# DDR16SS_DDR16SS_CTLPHY_WRAP_CTL_CFG_CTLCFG_0F308000h register map
Vendor: Texas Instruments
Registers are 32-bit, read-write, reset 0x0 unless marked. A register's access mark holds for its fields unless they carry their own. Offsets are as the file gives them; [hi:lo] are bit positions; lines under a group give offsets from that group; {n}, {i} and the like mark numbered series.

## DDR16SS_CTLPHY_WRAP_CTL_CFG_CTLCFG (part 4 of 11)
{0x0+4i} DDR16SS_CTLPHY_WRAP_CTL_CFG_CTLCFG_DENALI_CTL_{i} (i=239..241)
  [16:0] MR5_DATA_F{i-239}_1 — Data to program into memory mode register 5. FC={i-239} Reset Source: ctl_amod_g_rst_n
{0x0+4i} DDR16SS_CTLPHY_WRAP_CTL_CFG_CTLCFG_DENALI_CTL_{i} (i=242..244)
  [16:0] MR6_DATA_F{i-242}_0 — Data to program into memory mode register 6. FC={i-242} Reset Source: ctl_amod_g_rst_n
0x3D4 DDR16SS_CTLPHY_WRAP_CTL_CFG_CTLCFG_DENALI_CTL_245
  [16:0] MR6_DATA_F0_1 — Data to program into memory mode register 6. FC=0 Reset Source: ctl_amod_g_rst_n
0x3D8 DDR16SS_CTLPHY_WRAP_CTL_CFG_CTLCFG_DENALI_CTL_246
  [16:0] MR6_DATA_F1_1 — Data to program into memory mode register 6. FC=1 Reset Source: ctl_amod_g_rst_n
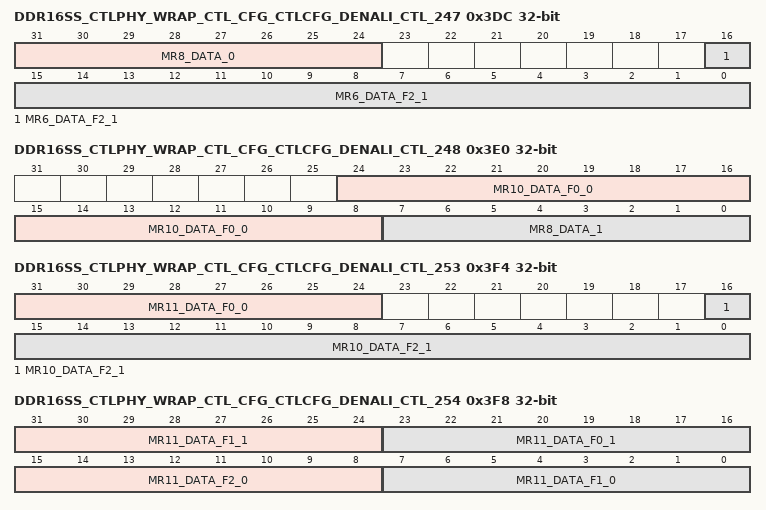
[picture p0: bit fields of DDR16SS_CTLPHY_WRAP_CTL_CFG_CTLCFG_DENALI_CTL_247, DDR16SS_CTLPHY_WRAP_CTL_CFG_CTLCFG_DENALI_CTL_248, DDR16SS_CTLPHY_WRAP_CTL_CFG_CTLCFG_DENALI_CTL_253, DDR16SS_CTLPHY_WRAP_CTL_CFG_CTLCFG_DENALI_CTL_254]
0x3DC DDR16SS_CTLPHY_WRAP_CTL_CFG_CTLCFG_DENALI_CTL_247 access per field
  [31:24] MR8_DATA_0 ro — Data to program into memory mode register 8 for each chip select. READ-ONLY. Reset Source: ctl_amod_g_rst_n
  [16:0] MR6_DATA_F2_1 rw — Data to program into memory mode register 6. FC=2 Reset Source: ctl_amod_g_rst_n
0x3E0 DDR16SS_CTLPHY_WRAP_CTL_CFG_CTLCFG_DENALI_CTL_248 access per field
  [24:8] MR10_DATA_F0_0 rw — Data to program into memory mode register 10. FC=0 Reset Source: ctl_amod_g_rst_n
  [7:0] MR8_DATA_1 ro — Data to program into memory mode register 8 for each chip select. READ-ONLY. Reset Source: ctl_amod_g_rst_n
0x3E4 DDR16SS_CTLPHY_WRAP_CTL_CFG_CTLCFG_DENALI_CTL_249
  [16:0] MR10_DATA_F1_0 — Data to program into memory mode register 10. FC=1 Reset Source: ctl_amod_g_rst_n
0x3E8 DDR16SS_CTLPHY_WRAP_CTL_CFG_CTLCFG_DENALI_CTL_250
  [16:0] MR10_DATA_F2_0 — Data to program into memory mode register 10. FC=2 Reset Source: ctl_amod_g_rst_n
0x3EC DDR16SS_CTLPHY_WRAP_CTL_CFG_CTLCFG_DENALI_CTL_251
  [16:0] MR10_DATA_F0_1 — Data to program into memory mode register 10. FC=0 Reset Source: ctl_amod_g_rst_n
0x3F0 DDR16SS_CTLPHY_WRAP_CTL_CFG_CTLCFG_DENALI_CTL_252
  [16:0] MR10_DATA_F1_1 — Data to program into memory mode register 10. FC=1 Reset Source: ctl_amod_g_rst_n
0x3F4 DDR16SS_CTLPHY_WRAP_CTL_CFG_CTLCFG_DENALI_CTL_253
  [31:24] MR11_DATA_F0_0 — Data to program into memory mode register 11. FC=0 Reset Source: ctl_amod_g_rst_n
  [16:0] MR10_DATA_F2_1 — Data to program into memory mode register 10. FC=2 Reset Source: ctl_amod_g_rst_n
0x3F8 DDR16SS_CTLPHY_WRAP_CTL_CFG_CTLCFG_DENALI_CTL_254
  [31:24] MR11_DATA_F1_1 — Data to program into memory mode register 11. FC=1 Reset Source: ctl_amod_g_rst_n
  [23:16] MR11_DATA_F0_1 — Data to program into memory mode register 11. FC=0 Reset Source: ctl_amod_g_rst_n
  [15:8] MR11_DATA_F2_0 — Data to program into memory mode register 11. FC=2 Reset Source: ctl_amod_g_rst_n
  [7:0] MR11_DATA_F1_0 — Data to program into memory mode register 11. FC=1 Reset Source: ctl_amod_g_rst_n
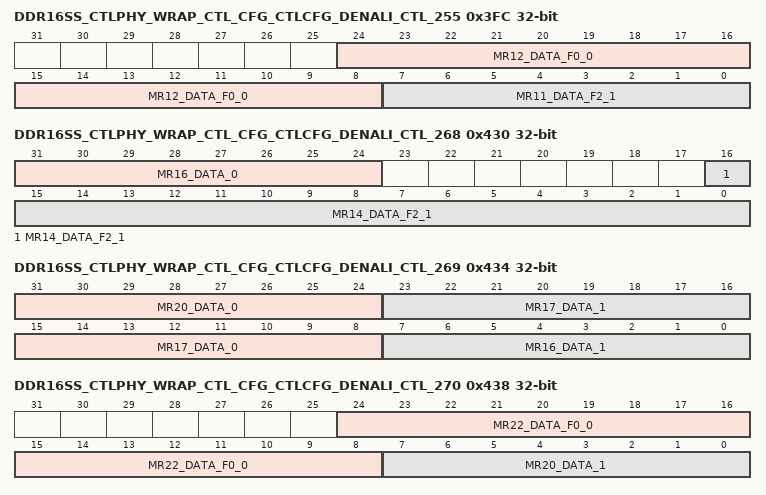
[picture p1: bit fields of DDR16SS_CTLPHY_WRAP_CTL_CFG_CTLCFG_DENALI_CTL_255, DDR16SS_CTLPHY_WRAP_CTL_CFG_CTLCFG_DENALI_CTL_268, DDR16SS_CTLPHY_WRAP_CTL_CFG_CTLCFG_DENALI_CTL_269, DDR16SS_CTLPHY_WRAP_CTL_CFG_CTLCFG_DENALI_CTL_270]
0x3FC DDR16SS_CTLPHY_WRAP_CTL_CFG_CTLCFG_DENALI_CTL_255
  [24:8] MR12_DATA_F0_0 — Data to program into memory mode register 12. FC=0 Reset Source: ctl_amod_g_rst_n
  [7:0] MR11_DATA_F2_1 — Data to program into memory mode register 11. FC=2 Reset Source: ctl_amod_g_rst_n
0x400 DDR16SS_CTLPHY_WRAP_CTL_CFG_CTLCFG_DENALI_CTL_256
  [16:0] MR12_DATA_F1_0 — Data to program into memory mode register 12. FC=1 Reset Source: ctl_amod_g_rst_n
0x404 DDR16SS_CTLPHY_WRAP_CTL_CFG_CTLCFG_DENALI_CTL_257
  [16:0] MR12_DATA_F2_0 — Data to program into memory mode register 12. FC=2 Reset Source: ctl_amod_g_rst_n
{0x0+4i} DDR16SS_CTLPHY_WRAP_CTL_CFG_CTLCFG_DENALI_CTL_{i} (i=258..260)
  [16:0] MR12_DATA_F{i-258}_1 — Data to program into memory mode register 12. FC={i-258} Reset Source: ctl_amod_g_rst_n
0x414 DDR16SS_CTLPHY_WRAP_CTL_CFG_CTLCFG_DENALI_CTL_261
  [16:0] MR13_DATA_0 — Data to program into memory mode register 13. Reset Source: ctl_amod_g_rst_n
0x418 DDR16SS_CTLPHY_WRAP_CTL_CFG_CTLCFG_DENALI_CTL_262
  [16:0] MR13_DATA_1 — Data to program into memory mode register 13. Reset Source: ctl_amod_g_rst_n
{0x0+4i} DDR16SS_CTLPHY_WRAP_CTL_CFG_CTLCFG_DENALI_CTL_{i} (i=263..265)
  [16:0] MR14_DATA_F{i-263}_0 — Data to program into memory mode register 14. FC={i-263} Reset Source: ctl_amod_g_rst_n
0x428 DDR16SS_CTLPHY_WRAP_CTL_CFG_CTLCFG_DENALI_CTL_266
  [16:0] MR14_DATA_F0_1 — Data to program into memory mode register 14. FC=0 Reset Source: ctl_amod_g_rst_n
0x42C DDR16SS_CTLPHY_WRAP_CTL_CFG_CTLCFG_DENALI_CTL_267
  [16:0] MR14_DATA_F1_1 — Data to program into memory mode register 14. FC=1 Reset Source: ctl_amod_g_rst_n
0x430 DDR16SS_CTLPHY_WRAP_CTL_CFG_CTLCFG_DENALI_CTL_268
  [31:24] MR16_DATA_0 — Data to program into memory mode register 16. Reset Source: ctl_amod_g_rst_n
  [16:0] MR14_DATA_F2_1 — Data to program into memory mode register 14. FC=2 Reset Source: ctl_amod_g_rst_n
0x434 DDR16SS_CTLPHY_WRAP_CTL_CFG_CTLCFG_DENALI_CTL_269
  [31:24] MR20_DATA_0 — Data to program into memory mode register 20. Reset Source: ctl_amod_g_rst_n
  [23:16] MR17_DATA_1 — Data to program into memory mode register 17. Reset Source: ctl_amod_g_rst_n
  [15:8] MR17_DATA_0 — Data to program into memory mode register 17. Reset Source: ctl_amod_g_rst_n
  [7:0] MR16_DATA_1 — Data to program into memory mode register 16. Reset Source: ctl_amod_g_rst_n
0x438 DDR16SS_CTLPHY_WRAP_CTL_CFG_CTLCFG_DENALI_CTL_270
  [24:8] MR22_DATA_F0_0 — Data to program into memory mode register 22. FC=0 Reset Source: ctl_amod_g_rst_n
  [7:0] MR20_DATA_1 — Data to program into memory mode register 20. Reset Source: ctl_amod_g_rst_n
0x43C DDR16SS_CTLPHY_WRAP_CTL_CFG_CTLCFG_DENALI_CTL_271
  [16:0] MR22_DATA_F1_0 — Data to program into memory mode register 22. FC=1 Reset Source: ctl_amod_g_rst_n
0x440 DDR16SS_CTLPHY_WRAP_CTL_CFG_CTLCFG_DENALI_CTL_272
  [16:0] MR22_DATA_F2_0 — Data to program into memory mode register 22. FC=2 Reset Source: ctl_amod_g_rst_n
{0x0+4i} DDR16SS_CTLPHY_WRAP_CTL_CFG_CTLCFG_DENALI_CTL_{i} (i=273..275)
  [16:0] MR22_DATA_F{i-273}_1 — Data to program into memory mode register 22. FC={i-273} Reset Source: ctl_amod_g_rst_n
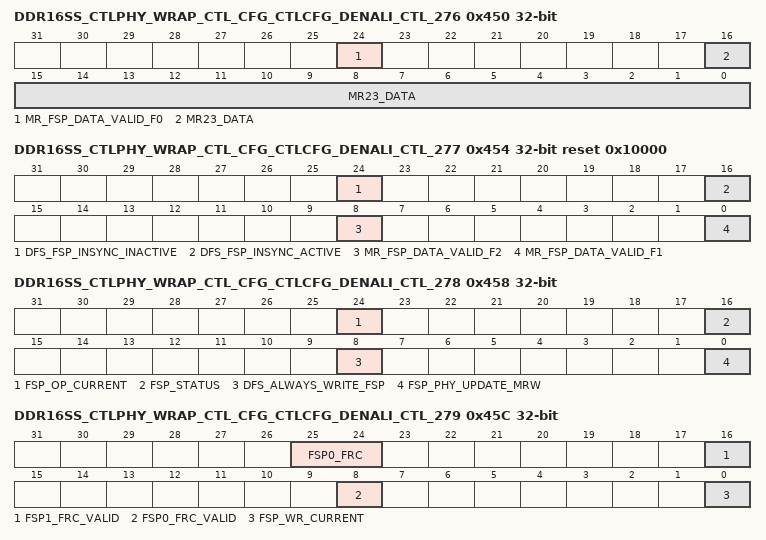
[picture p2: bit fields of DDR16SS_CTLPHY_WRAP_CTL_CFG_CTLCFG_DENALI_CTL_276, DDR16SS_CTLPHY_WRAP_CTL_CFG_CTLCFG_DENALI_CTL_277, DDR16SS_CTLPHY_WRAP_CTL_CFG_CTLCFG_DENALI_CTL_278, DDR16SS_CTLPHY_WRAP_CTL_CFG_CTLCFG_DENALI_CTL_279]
0x450 DDR16SS_CTLPHY_WRAP_CTL_CFG_CTLCFG_DENALI_CTL_276
  [24] MR_FSP_DATA_VALID_F0 — Indicates that, at this frequency, memory was trained and the associated data has been loaded into the MRx_DATA parameter[s]. Value of 1 means memory was trained. FC=0 Reset Source: ctl_amod_g_rst_n
  [16:0] MR23_DATA — Data to program into memory mode register 23. Reset Source: ctl_amod_g_rst_n
0x454 DDR16SS_CTLPHY_WRAP_CTL_CFG_CTLCFG_DENALI_CTL_277 access per field reset 0x10000
  [24] DFS_FSP_INSYNC_INACTIVE ro — When cleared, this indicates that the contents in memcd_param is new that the values in memory's MRx FSP reg and if a dfs occurs, they need to be updated. READ-ONLY Reset Source: ctl_amod_g_rst_n
  [16] DFS_FSP_INSYNC_ACTIVE ro — When cleared, this indicates that the contents in memcd_param is new that the values in memory's MRx FSP reg and if a dfs occurs, they need to be updated. READ-ONLY Reset Source: ctl_amod_g_rst_n
  [8] MR_FSP_DATA_VALID_F2 rw — Indicates that, at this frequency, memory was trained and the associated data has been loaded into the MRx_DATA parameter[s]. Value of 1 means memory was trained. FC=2 Reset Source: ctl_amod_g_rst_n
  [0] MR_FSP_DATA_VALID_F1 rw — Indicates that, at this frequency, memory was trained and the associated data has been loaded into the MRx_DATA parameter[s]. Value of 1 means memory was trained. FC=1 Reset Source: ctl_amod_g_rst_n
0x458 DDR16SS_CTLPHY_WRAP_CTL_CFG_CTLCFG_DENALI_CTL_278
  [24] FSP_OP_CURRENT — Reports which FSP set the memory is currently using. Reset Source: ctl_amod_g_rst_n
  [16] FSP_STATUS — Indicates that a DFS event caused the FSP mode registers to be updated. Value of 1 means that the FSP mode registers were changed. Reset Source: ctl_amod_g_rst_n
  [8] DFS_ALWAYS_WRITE_FSP — Forces all FSP mode registers to be written by the controller during a DFS event. Set to 1 to force the write. Reset Source: ctl_amod_g_rst_n
  [0] FSP_PHY_UPDATE_MRW — Identifies the logic responsible for updating MR12 and MR14 in memory. Clear to 0 for the controller, or set to 1 for the PHY or PI. Reset Source: ctl_amod_g_rst_n
0x45C DDR16SS_CTLPHY_WRAP_CTL_CFG_CTLCFG_DENALI_CTL_279
  [25:24] FSP0_FRC — Identifies which of the controller's frequency copy is associated with FSP0. Reset Source: ctl_amod_g_rst_n
  [16] FSP1_FRC_VALID — Specifies whether the FSP set defined in the FSP1_FRC parameter reflects the frequency used to program the FSP1 registers. Reset Source: ctl_amod_g_rst_n
  [8] FSP0_FRC_VALID — Specifies whether the FSP set defined in the FSP0_FRC parameter reflects the frequency used to program the FSP0 registers. Reset Source: ctl_amod_g_rst_n
  [0] FSP_WR_CURRENT — Reports which FSP set the memory will target with write commands. Reset Source: ctl_amod_g_rst_n
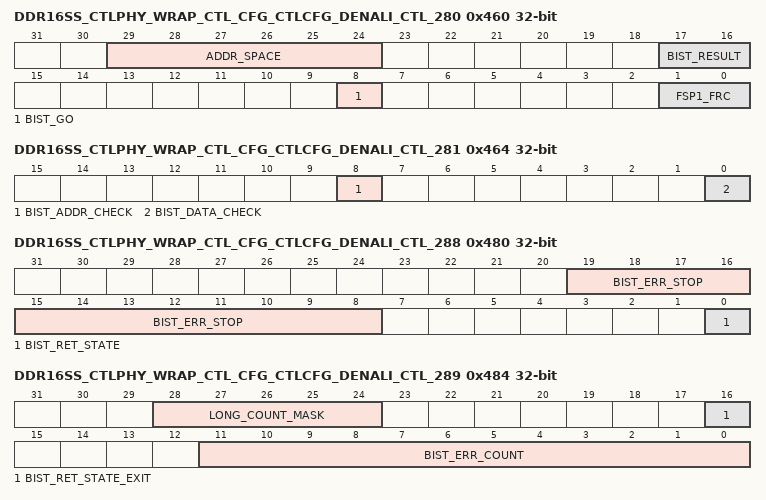
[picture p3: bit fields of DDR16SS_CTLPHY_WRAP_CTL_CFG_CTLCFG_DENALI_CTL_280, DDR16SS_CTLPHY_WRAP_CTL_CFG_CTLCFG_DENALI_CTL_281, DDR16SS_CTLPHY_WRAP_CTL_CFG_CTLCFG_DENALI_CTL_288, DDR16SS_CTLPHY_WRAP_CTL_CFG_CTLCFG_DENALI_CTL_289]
0x460 DDR16SS_CTLPHY_WRAP_CTL_CFG_CTLCFG_DENALI_CTL_280 access per field
  [29:24] ADDR_SPACE rw — Sets the number of address bits to check during BIST operation. Reset Source: ctl_amod_g_rst_n
  [17:16] BIST_RESULT ro — BIST operation status [pass/fail]. Bit [0] indicates data check status and bit [1] indicates address check status. Value of 1 is a passing result. READ-ONLY Reset Source: ctl_amod_g_rst_n
  [8] BIST_GO wo — Initiate a BIST operation. Set to 1 to trigger. WRITE-ONLY Reset Source: ctl_amod_g_rst_n
  [1:0] FSP1_FRC rw — Identifies which of the controller's frequency copy is associated with FSP1. Reset Source: ctl_amod_g_rst_n
0x464 DDR16SS_CTLPHY_WRAP_CTL_CFG_CTLCFG_DENALI_CTL_281
  [8] BIST_ADDR_CHECK — Enable address checking with BIST operation. Set to 1 to enable. Reset Source: ctl_amod_g_rst_n
  [0] BIST_DATA_CHECK — Enable data checking with BIST operation. Set to 1 to enable. Reset Source: ctl_amod_g_rst_n
0x468 DDR16SS_CTLPHY_WRAP_CTL_CFG_CTLCFG_DENALI_CTL_282
  [31:0] BIST_START_ADDRESS_0 — Start BIST checking at this address. Reset Source: ctl_amod_g_rst_n
0x46C DDR16SS_CTLPHY_WRAP_CTL_CFG_CTLCFG_DENALI_CTL_283
  [0] BIST_START_ADDRESS_1 — Start BIST checking at this address. Reset Source: ctl_amod_g_rst_n
0x470 DDR16SS_CTLPHY_WRAP_CTL_CFG_CTLCFG_DENALI_CTL_284
  [31:0] BIST_DATA_MASK — Mask applied to data for BIST error checking. Bit [0] controls memory data path bit [0], bit [1] controls memory data path bit [1], etc. Set each bit to 1 to mask. Reset Source: ctl_amod_g_rst_n
0x474 DDR16SS_CTLPHY_WRAP_CTL_CFG_CTLCFG_DENALI_CTL_285
  [2:0] BIST_TEST_MODE — Sets the BIST test mode. Value of 0 specifies standard BIST operation, value of 1 specifies a reduced BIST operation, value of 2 specifies a self-refresh retention test, value of 3 specifies an idle retention test, and value of 4 specifies memory initalization function. All other values are reserved. Reset Source: ctl_amod_g_rst_n
0x478 DDR16SS_CTLPHY_WRAP_CTL_CFG_CTLCFG_DENALI_CTL_286
  [31:0] BIST_DATA_PATTERN_0 — Data pattern to be used when the BIST_TEST_MODE parameter is programmed to 1, 2, 3 or 4. Only data corresponding to active portion of core word will be used while inactive portion will be ignored. Reset Source: ctl_amod_g_rst_n
0x47C DDR16SS_CTLPHY_WRAP_CTL_CFG_CTLCFG_DENALI_CTL_287
  [31:0] BIST_DATA_PATTERN_1 — Data pattern to be used when the BIST_TEST_MODE parameter is programmed to 1, 2, 3 or 4. Only data corresponding to active portion of core word will be used while inactive portion will be ignored. Reset Source: ctl_amod_g_rst_n
0x480 DDR16SS_CTLPHY_WRAP_CTL_CFG_CTLCFG_DENALI_CTL_288 access per field
  [19:8] BIST_ERR_STOP rw — Defines the maximum number of error occurrences allowed prior to quitting when the BIST_TEST_MODE parameter is programmed to 1, 2 or 3. A value of 0 will allow the test to run to completion. Reset Source: ctl_amod_g_rst_n
  [0] BIST_RET_STATE ro — Indicates if BIST is in a retention wait state, used when the BIST_TEST_MODE parameter is programmed to 2 or 3. Value of 1 indicates BIST is waiting. READ-ONLY Reset Source: ctl_amod_g_rst_n
0x484 DDR16SS_CTLPHY_WRAP_CTL_CFG_CTLCFG_DENALI_CTL_289 access per field
  [28:24] LONG_COUNT_MASK rw — Reduces the length of the long counter from 1024 cycles. The only supported values are 0x00 [1024 cycles], 0x10 [512 clocks], 0x18 [256 clocks], 0x1C [128 clocks], 0x1E [64 clocks] and 0x1F [32 clocks]. Reset Source: ctl_amod_g_rst_n
  [16] BIST_RET_STATE_EXIT wo — Exit self-refresh or idle retention state, used when the BIST_TEST_MODE parameter is programmed to 2 or 3. Set to 1 to trigger. WRITE-ONLY Reset Source: ctl_amod_g_rst_n
  [11:0] BIST_ERR_COUNT ro — Indicates the number of BIST errors found when the BIST_TEST_MODE parameter is programmed to 1, 2 or 3. READ-ONLY Reset Source: ctl_amod_g_rst_n
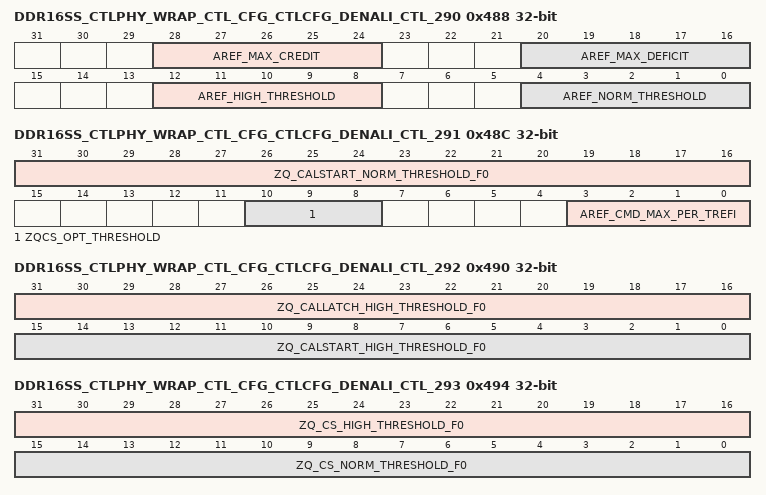
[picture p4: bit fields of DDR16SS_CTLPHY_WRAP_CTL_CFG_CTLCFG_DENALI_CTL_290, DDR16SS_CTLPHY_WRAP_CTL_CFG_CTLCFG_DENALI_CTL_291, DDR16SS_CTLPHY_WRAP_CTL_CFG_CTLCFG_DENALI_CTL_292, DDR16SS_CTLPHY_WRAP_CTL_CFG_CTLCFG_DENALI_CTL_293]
0x488 DDR16SS_CTLPHY_WRAP_CTL_CFG_CTLCFG_DENALI_CTL_290
  [28:24] AREF_MAX_CREDIT — AREF number of posted refreshes until the maximum number of refresh credits has been reached. Reset Source: ctl_amod_g_rst_n
  [20:16] AREF_MAX_DEFICIT — AREF number of pending refreshes until the maximum number of refreshes has been exceeded. Reset Source: ctl_amod_g_rst_n
  [12:8] AREF_HIGH_THRESHOLD — AREF number of pending refreshes until the high priority request is asserted. Reset Source: ctl_amod_g_rst_n
  [4:0] AREF_NORM_THRESHOLD — AREF number of pending refreshes until the normal priority request is asserted. Reset Source: ctl_amod_g_rst_n
0x48C DDR16SS_CTLPHY_WRAP_CTL_CFG_CTLCFG_DENALI_CTL_291
  [31:16] ZQ_CALSTART_NORM_THRESHOLD_F0 — ZQ START number of long counts until the normal priority request is asserted. This value should be scaled based on the number of ranks [chip selects] the controller handles. The more chip selects there are, the more rotations there are to go through, and the smaller this threshold should be. FC=0 Reset Source: ctl_amod_g_rst_n
  [10:8] ZQCS_OPT_THRESHOLD — Number of clocks before ZQCS expires when the ZQ task will deassert its request for optimal command to command turn-around timing. Reset Source: ctl_amod_g_rst_n
  [3:0] AREF_CMD_MAX_PER_TREFI — Sets the maximum number of auto-refreshes that will be executed in a TREFI period - both normal and high priority. This does not prevent refreshes generated by sub-task requests such as a self-refresh exit and enter. Reset Source: ctl_amod_g_rst_n
0x490 DDR16SS_CTLPHY_WRAP_CTL_CFG_CTLCFG_DENALI_CTL_292
  [31:16] ZQ_CALLATCH_HIGH_THRESHOLD_F0 — ZQ LATCH number of long counts until the high priority request is asserted. FC=0 Reset Source: ctl_amod_g_rst_n
  [15:0] ZQ_CALSTART_HIGH_THRESHOLD_F0 — ZQ START number of long counts until the high priority request is asserted. FC=0 Reset Source: ctl_amod_g_rst_n
0x494 DDR16SS_CTLPHY_WRAP_CTL_CFG_CTLCFG_DENALI_CTL_293
  [31:16] ZQ_CS_HIGH_THRESHOLD_F0 — ZQ CS number of long counts until the high priority request is asserted. FC=0 Reset Source: ctl_amod_g_rst_n
  [15:0] ZQ_CS_NORM_THRESHOLD_F0 — ZQ CS number of long counts until the normal priority request is asserted. FC=0 Reset Source: ctl_amod_g_rst_n
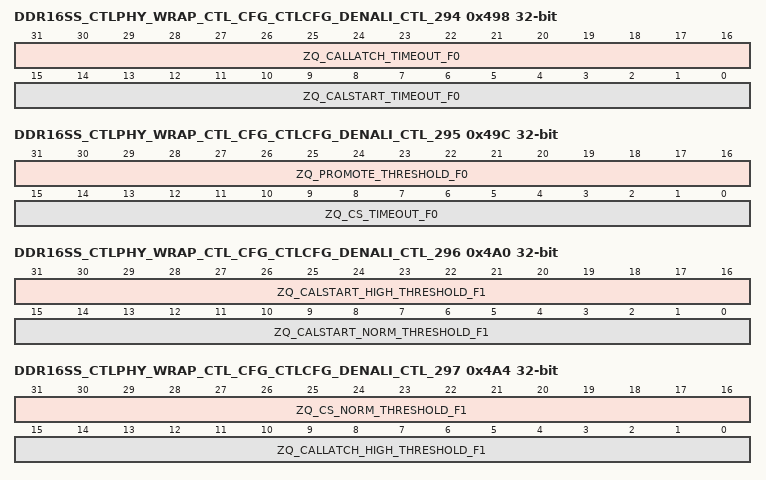
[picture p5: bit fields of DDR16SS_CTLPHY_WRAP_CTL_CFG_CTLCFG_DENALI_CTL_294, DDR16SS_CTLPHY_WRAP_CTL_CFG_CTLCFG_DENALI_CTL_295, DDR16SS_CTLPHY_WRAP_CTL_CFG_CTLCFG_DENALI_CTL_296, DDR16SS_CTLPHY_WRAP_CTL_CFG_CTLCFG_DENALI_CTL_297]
0x498 DDR16SS_CTLPHY_WRAP_CTL_CFG_CTLCFG_DENALI_CTL_294
  [31:16] ZQ_CALLATCH_TIMEOUT_F0 — ZQ LATCH number of long counts until the timeout is asserted. FC=0 Reset Source: ctl_amod_g_rst_n
  [15:0] ZQ_CALSTART_TIMEOUT_F0 — ZQ START number of long counts until the timeout is asserted. FC=0 Reset Source: ctl_amod_g_rst_n
0x49C DDR16SS_CTLPHY_WRAP_CTL_CFG_CTLCFG_DENALI_CTL_295
  [31:16] ZQ_PROMOTE_THRESHOLD_F0 — ZQ SW promotion number of long counts until the high priority request is asserted. FC=0 Reset Source: ctl_amod_g_rst_n
  [15:0] ZQ_CS_TIMEOUT_F0 — ZQ CS number of long counts until the timeout is asserted. FC=0 Reset Source: ctl_amod_g_rst_n
0x4A0 DDR16SS_CTLPHY_WRAP_CTL_CFG_CTLCFG_DENALI_CTL_296
  [31:16] ZQ_CALSTART_HIGH_THRESHOLD_F1 — ZQ START number of long counts until the high priority request is asserted. FC=1 Reset Source: ctl_amod_g_rst_n
  [15:0] ZQ_CALSTART_NORM_THRESHOLD_F1 — ZQ START number of long counts until the normal priority request is asserted. This value should be scaled based on the number of ranks [chip selects] the controller handles. The more chip selects there are, the more rotations there are to go through, and the smaller this threshold should be. FC=1 Reset Source: ctl_amod_g_rst_n
0x4A4 DDR16SS_CTLPHY_WRAP_CTL_CFG_CTLCFG_DENALI_CTL_297
  [31:16] ZQ_CS_NORM_THRESHOLD_F1 — ZQ CS number of long counts until the normal priority request is asserted. FC=1 Reset Source: ctl_amod_g_rst_n
  [15:0] ZQ_CALLATCH_HIGH_THRESHOLD_F1 — ZQ LATCH number of long counts until the high priority request is asserted. FC=1 Reset Source: ctl_amod_g_rst_n
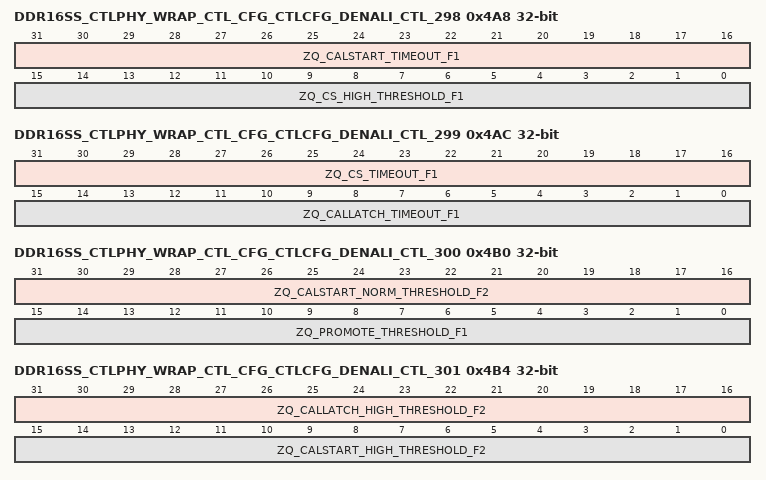
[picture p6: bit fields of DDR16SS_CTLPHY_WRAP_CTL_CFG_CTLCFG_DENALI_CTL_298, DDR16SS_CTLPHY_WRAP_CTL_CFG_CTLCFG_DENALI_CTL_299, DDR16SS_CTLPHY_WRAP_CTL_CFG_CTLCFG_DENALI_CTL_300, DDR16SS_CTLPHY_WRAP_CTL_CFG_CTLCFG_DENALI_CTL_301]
0x4A8 DDR16SS_CTLPHY_WRAP_CTL_CFG_CTLCFG_DENALI_CTL_298
  [31:16] ZQ_CALSTART_TIMEOUT_F1 — ZQ START number of long counts until the timeout is asserted. FC=1 Reset Source: ctl_amod_g_rst_n
  [15:0] ZQ_CS_HIGH_THRESHOLD_F1 — ZQ CS number of long counts until the high priority request is asserted. FC=1 Reset Source: ctl_amod_g_rst_n
0x4AC DDR16SS_CTLPHY_WRAP_CTL_CFG_CTLCFG_DENALI_CTL_299
  [31:16] ZQ_CS_TIMEOUT_F1 — ZQ CS number of long counts until the timeout is asserted. FC=1 Reset Source: ctl_amod_g_rst_n
  [15:0] ZQ_CALLATCH_TIMEOUT_F1 — ZQ LATCH number of long counts until the timeout is asserted. FC=1 Reset Source: ctl_amod_g_rst_n
0x4B0 DDR16SS_CTLPHY_WRAP_CTL_CFG_CTLCFG_DENALI_CTL_300
  [31:16] ZQ_CALSTART_NORM_THRESHOLD_F2 — ZQ START number of long counts until the normal priority request is asserted. This value should be scaled based on the number of ranks [chip selects] the controller handles. The more chip selects there are, the more rotations there are to go through, and the smaller this threshold should be. FC=2 Reset Source: ctl_amod_g_rst_n
  [15:0] ZQ_PROMOTE_THRESHOLD_F1 — ZQ SW promotion number of long counts until the high priority request is asserted. FC=1 Reset Source: ctl_amod_g_rst_n
0x4B4 DDR16SS_CTLPHY_WRAP_CTL_CFG_CTLCFG_DENALI_CTL_301
  [31:16] ZQ_CALLATCH_HIGH_THRESHOLD_F2 — ZQ LATCH number of long counts until the high priority request is asserted. FC=2 Reset Source: ctl_amod_g_rst_n
  [15:0] ZQ_CALSTART_HIGH_THRESHOLD_F2 — ZQ START number of long counts until the high priority request is asserted. FC=2 Reset Source: ctl_amod_g_rst_n
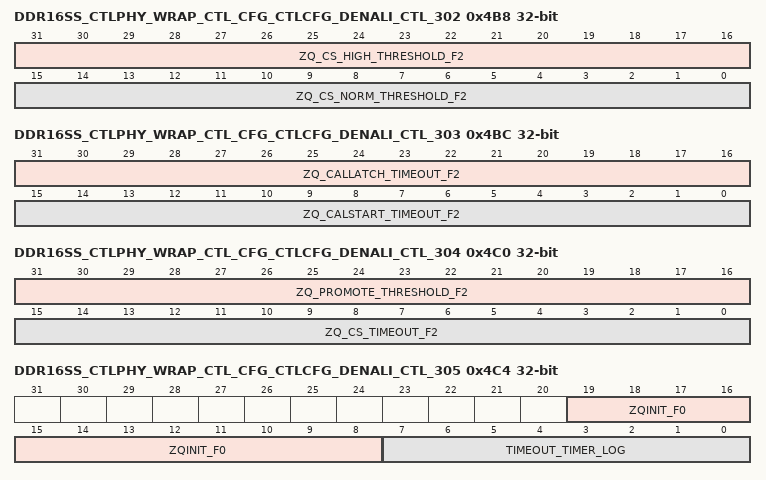
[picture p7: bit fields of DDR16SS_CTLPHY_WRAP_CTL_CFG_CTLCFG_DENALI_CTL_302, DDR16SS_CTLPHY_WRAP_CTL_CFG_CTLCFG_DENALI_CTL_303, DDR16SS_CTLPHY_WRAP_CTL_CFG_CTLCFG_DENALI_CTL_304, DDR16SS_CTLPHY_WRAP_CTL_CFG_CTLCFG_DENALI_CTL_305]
0x4B8 DDR16SS_CTLPHY_WRAP_CTL_CFG_CTLCFG_DENALI_CTL_302
  [31:16] ZQ_CS_HIGH_THRESHOLD_F2 — ZQ CS number of long counts until the high priority request is asserted. FC=2 Reset Source: ctl_amod_g_rst_n
  [15:0] ZQ_CS_NORM_THRESHOLD_F2 — ZQ CS number of long counts until the normal priority request is asserted. FC=2 Reset Source: ctl_amod_g_rst_n
0x4BC DDR16SS_CTLPHY_WRAP_CTL_CFG_CTLCFG_DENALI_CTL_303
  [31:16] ZQ_CALLATCH_TIMEOUT_F2 — ZQ LATCH number of long counts until the timeout is asserted. FC=2 Reset Source: ctl_amod_g_rst_n
  [15:0] ZQ_CALSTART_TIMEOUT_F2 — ZQ START number of long counts until the timeout is asserted. FC=2 Reset Source: ctl_amod_g_rst_n
0x4C0 DDR16SS_CTLPHY_WRAP_CTL_CFG_CTLCFG_DENALI_CTL_304
  [31:16] ZQ_PROMOTE_THRESHOLD_F2 — ZQ SW promotion number of long counts until the high priority request is asserted. FC=2 Reset Source: ctl_amod_g_rst_n
  [15:0] ZQ_CS_TIMEOUT_F2 — ZQ CS number of long counts until the timeout is asserted. FC=2 Reset Source: ctl_amod_g_rst_n
0x4C4 DDR16SS_CTLPHY_WRAP_CTL_CFG_CTLCFG_DENALI_CTL_305 access per field
  [19:8] ZQINIT_F0 rw — Number of cycles needed for a ZQINIT command. FC=0 Reset Source: ctl_amod_g_rst_n
  [7:0] TIMEOUT_TIMER_LOG ro — Reflects which timers experienced a timeout error [or had an uncleared error] when the timeout interrupt fired. Bit [0] correlates to a ZQ cal init, cs, cl, or reset FM timeout. Bit [1] correlates to the ZQ calstart FM timeout. Bit [2] correlates to the ZQ callatch FM timeout. Bit [3] correlates to the MRR temperature check FM timeout. Bit [4] correlates to the DQS oscillator FM timeout. Bit [5] correlates to the DFI update FM timeout. Bit [6] correlates to the low power interface wakeup timeout. Bit [7] correlates to the auto refresh max deficit timeout. READ-ONLY Reset Source: ctl_amod_g_rst_n
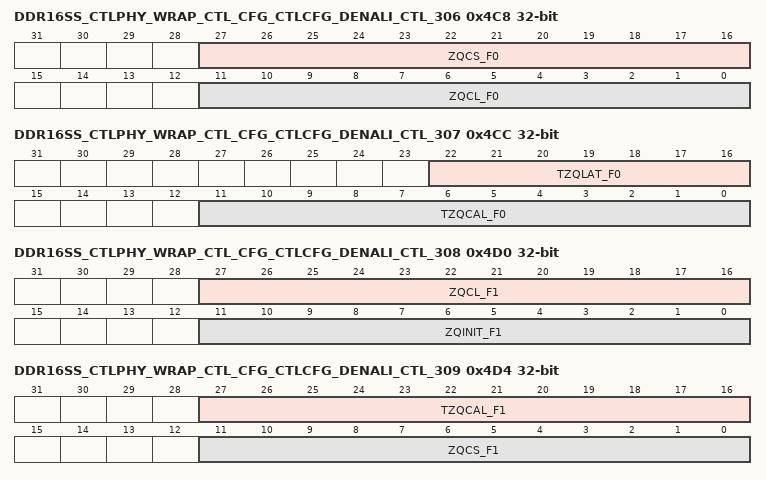
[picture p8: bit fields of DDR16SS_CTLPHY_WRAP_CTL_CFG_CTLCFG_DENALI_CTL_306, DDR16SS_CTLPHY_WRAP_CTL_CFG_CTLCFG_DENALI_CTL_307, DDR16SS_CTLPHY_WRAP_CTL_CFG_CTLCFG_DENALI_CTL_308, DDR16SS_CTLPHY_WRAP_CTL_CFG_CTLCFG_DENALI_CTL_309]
0x4C8 DDR16SS_CTLPHY_WRAP_CTL_CFG_CTLCFG_DENALI_CTL_306
  [27:16] ZQCS_F0 — Number of cycles needed for a ZQCS command. FC=0 Reset Source: ctl_amod_g_rst_n
  [11:0] ZQCL_F0 — Number of cycles needed for a ZQCL command. FC=0 Reset Source: ctl_amod_g_rst_n
0x4CC DDR16SS_CTLPHY_WRAP_CTL_CFG_CTLCFG_DENALI_CTL_307
  [22:16] TZQLAT_F0 — Holds the DRAM ZQLAT value in cycles. FC=0 Reset Source: ctl_amod_g_rst_n
  [11:0] TZQCAL_F0 — Holds the DRAM ZQCAL value in cycles. FC=0 Reset Source: ctl_amod_g_rst_n
0x4D0 DDR16SS_CTLPHY_WRAP_CTL_CFG_CTLCFG_DENALI_CTL_308
  [27:16] ZQCL_F1 — Number of cycles needed for a ZQCL command. FC=1 Reset Source: ctl_amod_g_rst_n
  [11:0] ZQINIT_F1 — Number of cycles needed for a ZQINIT command. FC=1 Reset Source: ctl_amod_g_rst_n
0x4D4 DDR16SS_CTLPHY_WRAP_CTL_CFG_CTLCFG_DENALI_CTL_309
  [27:16] TZQCAL_F1 — Holds the DRAM ZQCAL value in cycles. FC=1 Reset Source: ctl_amod_g_rst_n
  [11:0] ZQCS_F1 — Number of cycles needed for a ZQCS command. FC=1 Reset Source: ctl_amod_g_rst_n
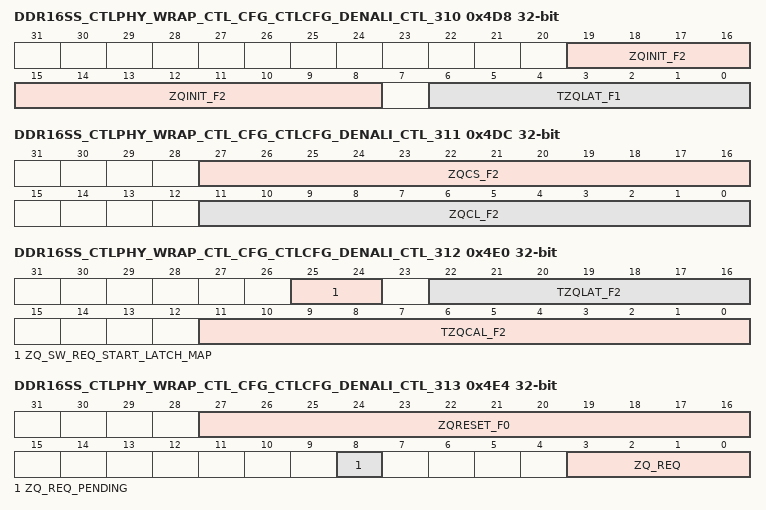
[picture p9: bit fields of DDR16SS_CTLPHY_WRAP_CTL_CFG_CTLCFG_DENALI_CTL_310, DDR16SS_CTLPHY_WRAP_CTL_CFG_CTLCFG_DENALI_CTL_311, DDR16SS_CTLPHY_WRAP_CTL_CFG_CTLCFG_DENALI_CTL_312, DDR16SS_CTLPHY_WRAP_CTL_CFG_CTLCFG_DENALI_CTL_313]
0x4D8 DDR16SS_CTLPHY_WRAP_CTL_CFG_CTLCFG_DENALI_CTL_310
  [19:8] ZQINIT_F2 — Number of cycles needed for a ZQINIT command. FC=2 Reset Source: ctl_amod_g_rst_n
  [6:0] TZQLAT_F1 — Holds the DRAM ZQLAT value in cycles. FC=1 Reset Source: ctl_amod_g_rst_n
0x4DC DDR16SS_CTLPHY_WRAP_CTL_CFG_CTLCFG_DENALI_CTL_311
  [27:16] ZQCS_F2 — Number of cycles needed for a ZQCS command. FC=2 Reset Source: ctl_amod_g_rst_n
  [11:0] ZQCL_F2 — Number of cycles needed for a ZQCL command. FC=2 Reset Source: ctl_amod_g_rst_n
0x4E0 DDR16SS_CTLPHY_WRAP_CTL_CFG_CTLCFG_DENALI_CTL_312
  [25:24] ZQ_SW_REQ_START_LATCH_MAP — Specifies which chip selects will simultaneously receive a ZQ start or latch command once the ZQ_REQ parameter is written with a ZQ Start or ZQ Latch command. Reset Source: ctl_amod_g_rst_n
  [22:16] TZQLAT_F2 — Holds the DRAM ZQLAT value in cycles. FC=2 Reset Source: ctl_amod_g_rst_n
  [11:0] TZQCAL_F2 — Holds the DRAM ZQCAL value in cycles. FC=2 Reset Source: ctl_amod_g_rst_n
0x4E4 DDR16SS_CTLPHY_WRAP_CTL_CFG_CTLCFG_DENALI_CTL_313 access per field
  [27:16] ZQRESET_F0 rw — Number of cycles needed for a ZQRESET command. FC=0 Reset Source: ctl_amod_g_rst_n
  [8] ZQ_REQ_PENDING ro — Indicates that a ZQ command is currently in progress or waiting to run. Value of 1 indicates command in progress or waiting to run. When this is asserted, no writes to ZQ_REQ should occur. READ-ONLY Reset Source: ctl_amod_g_rst_n
  [3:0] ZQ_REQ wo — User request to initiate a ZQ calibration. Program to 3 for ZQ Start, program to 4 for ZQ Initialization [ZQINIT], program to 5 for ZQ Latch, or program to 8 for ZQ Reset. Clearing to 0 will not trigger any ZQ command. This parameter should only be written when the ZQ_REQ_PENDING parameter is cleared to 0. WRITE-ONLY Reset Source: ctl_amod_g_rst_n
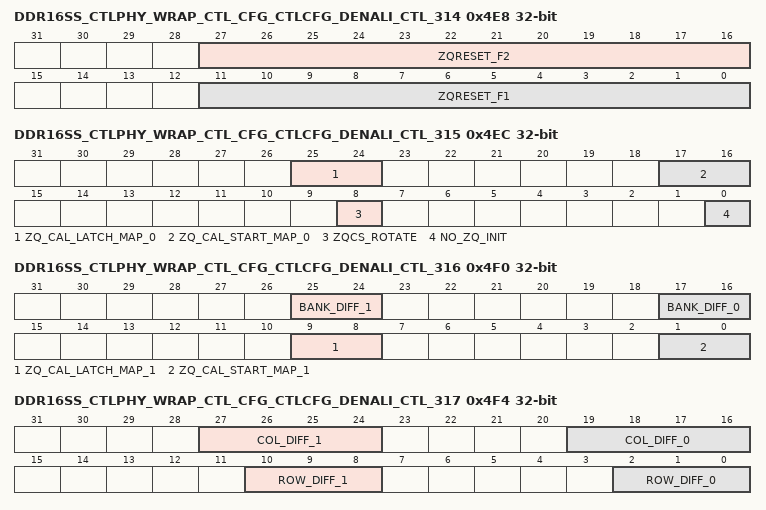
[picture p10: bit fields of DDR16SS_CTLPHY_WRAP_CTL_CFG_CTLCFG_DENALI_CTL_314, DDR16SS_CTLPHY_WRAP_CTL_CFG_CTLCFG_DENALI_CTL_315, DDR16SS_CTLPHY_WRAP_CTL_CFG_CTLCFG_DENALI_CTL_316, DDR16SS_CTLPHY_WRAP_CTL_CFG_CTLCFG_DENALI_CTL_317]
0x4E8 DDR16SS_CTLPHY_WRAP_CTL_CFG_CTLCFG_DENALI_CTL_314
  [27:16] ZQRESET_F2 — Number of cycles needed for a ZQRESET command. FC=2 Reset Source: ctl_amod_g_rst_n
  [11:0] ZQRESET_F1 — Number of cycles needed for a ZQRESET command. FC=1 Reset Source: ctl_amod_g_rst_n
0x4EC DDR16SS_CTLPHY_WRAP_CTL_CFG_CTLCFG_DENALI_CTL_315
  [25:24] ZQ_CAL_LATCH_MAP_0 — Defines which chip select[s] will receive ZQ calibration latch commands simultaneously on iteration 0 of the ZQ LATCH initialization and periodic command sequences. Clear to all zeros for no ZQ LATCH commands. CS=0 Reset Source: ctl_amod_g_rst_n
  [17:16] ZQ_CAL_START_MAP_0 — Defines which chip select[s] will receive ZQ calibration start commands simultaneously on iteration 0 of the ZQ START initialization and periodic command sequences. Clear to all zeros for no ZQ START commands. CS=0 Reset Source: ctl_amod_g_rst_n
  [8] ZQCS_ROTATE — For memories that perform ZQ short commands [ZQCS], selects whether a ZQCS command will calibrate just one chip select or all chip selects. When rotation is off, all chip selects will be calibrated, requiring a longer time frame, but ZQ calibration will need to be performed less frequently. Set to 1 for rotating CS. For ZQ start/latch memories, this parameter is ignored. Reset Source: ctl_amod_g_rst_n
  [0] NO_ZQ_INIT — Disable ZQ operations during initialization. Set to 1 to disable. Reset Source: ctl_amod_g_rst_n
0x4F0 DDR16SS_CTLPHY_WRAP_CTL_CFG_CTLCFG_DENALI_CTL_316
  [25:24] BANK_DIFF_1 — Encoded number of banks on the DRAM[s]. Reset Source: ctl_amod_g_rst_n
  [17:16] BANK_DIFF_0 — Encoded number of banks on the DRAM[s]. Reset Source: ctl_amod_g_rst_n
  [9:8] ZQ_CAL_LATCH_MAP_1 — Defines which chip select[s] will receive ZQ calibration latch commands simultaneously on iteration 1 of the ZQ LATCH initialization and periodic command sequences. Clear to all zeros for no ZQ LATCH commands. CS=1 Reset Source: ctl_amod_g_rst_n
  [1:0] ZQ_CAL_START_MAP_1 — Defines which chip select[s] will receive ZQ calibration start commands simultaneously on iteration 1 of the ZQ START initialization and periodic command sequences. Clear to all zeros for no ZQ START commands. CS=1 Reset Source: ctl_amod_g_rst_n
0x4F4 DDR16SS_CTLPHY_WRAP_CTL_CFG_CTLCFG_DENALI_CTL_317
  [27:24] COL_DIFF_1 — Difference between number of column pins available and number being used. Reset Source: ctl_amod_g_rst_n
  [19:16] COL_DIFF_0 — Difference between number of column pins available and number being used. Reset Source: ctl_amod_g_rst_n
  [10:8] ROW_DIFF_1 — Difference between number of address pins available and number being used. Reset Source: ctl_amod_g_rst_n
  [2:0] ROW_DIFF_0 — Difference between number of address pins available and number being used. Reset Source: ctl_amod_g_rst_n
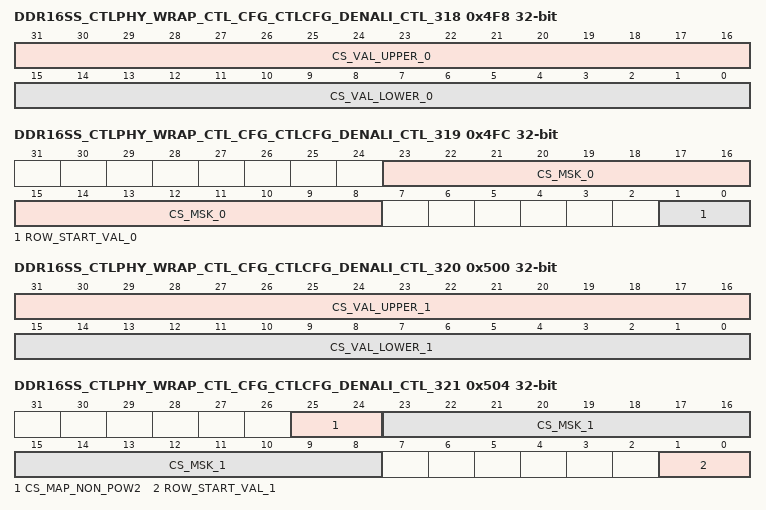
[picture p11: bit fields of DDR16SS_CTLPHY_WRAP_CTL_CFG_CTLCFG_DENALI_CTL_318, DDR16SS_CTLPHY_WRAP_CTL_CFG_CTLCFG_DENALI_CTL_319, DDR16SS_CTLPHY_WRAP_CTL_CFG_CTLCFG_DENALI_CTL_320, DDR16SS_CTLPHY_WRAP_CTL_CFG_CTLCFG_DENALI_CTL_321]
0x4F8 DDR16SS_CTLPHY_WRAP_CTL_CFG_CTLCFG_DENALI_CTL_318
  [31:16] CS_VAL_UPPER_0 — Upper bound address for chip select 0. Reset Source: ctl_amod_g_rst_n
  [15:0] CS_VAL_LOWER_0 — Lower bound address for chip select 0. Reset Source: ctl_amod_g_rst_n
0x4FC DDR16SS_CTLPHY_WRAP_CTL_CFG_CTLCFG_DENALI_CTL_319
  [23:8] CS_MSK_0 — Mask applied to the address decode for chip select 0. Reset Source: ctl_amod_g_rst_n
  [1:0] ROW_START_VAL_0 — Row start value for chip select 0. Reset Source: ctl_amod_g_rst_n
0x500 DDR16SS_CTLPHY_WRAP_CTL_CFG_CTLCFG_DENALI_CTL_320
  [31:16] CS_VAL_UPPER_1 — Upper bound address for chip select 1. Reset Source: ctl_amod_g_rst_n
  [15:0] CS_VAL_LOWER_1 — Lower bound address for chip select 1. Reset Source: ctl_amod_g_rst_n
0x504 DDR16SS_CTLPHY_WRAP_CTL_CFG_CTLCFG_DENALI_CTL_321
  [25:24] CS_MAP_NON_POW2 — Defines which chip selects are non-power-of-2 memory sizes. Reset Source: ctl_amod_g_rst_n
  [23:8] CS_MSK_1 — Mask applied to the address decode for chip select 1. Reset Source: ctl_amod_g_rst_n
  [1:0] ROW_START_VAL_1 — Row start value for chip select 1. Reset Source: ctl_amod_g_rst_n
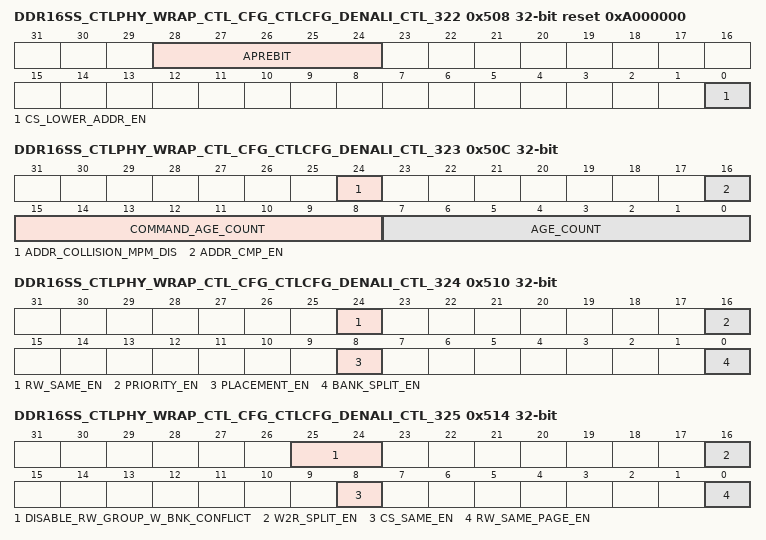
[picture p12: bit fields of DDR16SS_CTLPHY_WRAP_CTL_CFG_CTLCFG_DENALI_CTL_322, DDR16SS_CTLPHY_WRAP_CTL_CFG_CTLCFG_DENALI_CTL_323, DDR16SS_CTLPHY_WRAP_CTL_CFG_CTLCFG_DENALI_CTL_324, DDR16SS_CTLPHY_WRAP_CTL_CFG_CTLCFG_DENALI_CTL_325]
0x508 DDR16SS_CTLPHY_WRAP_CTL_CFG_CTLCFG_DENALI_CTL_322 reset 0xA000000
  [28:24] APREBIT — Location of the auto pre-charge bit in the DRAM address. Reset Source: ctl_amod_g_rst_n
  [0] CS_LOWER_ADDR_EN — Enables moving the CS field to lower in the address map. When set to 1, the memory address map will be changed to ROW__CS__BANK. Please refer to the limitations before setting this bit. Reset Source: ctl_amod_g_rst_n
0x50C DDR16SS_CTLPHY_WRAP_CTL_CFG_CTLCFG_DENALI_CTL_323
  [24] ADDR_COLLISION_MPM_DIS — Disable address collision detection extension using micro page mask for command queue placement and selection. Set to 1 to disable. Reset Source: ctl_amod_g_rst_n
  [16] ADDR_CMP_EN — Enable address collision detection as a rule for command queue placement. Set to 1 to enable. Reset Source: ctl_amod_g_rst_n
  [15:8] COMMAND_AGE_COUNT — Initial value of individual command aging counters for command aging. Reset Source: ctl_amod_g_rst_n
  [7:0] AGE_COUNT — Initial value of master aging-rate counter for command aging. Reset Source: ctl_amod_g_rst_n
0x510 DDR16SS_CTLPHY_WRAP_CTL_CFG_CTLCFG_DENALI_CTL_324
  [24] RW_SAME_EN — Enable read/write grouping as a rule for command queue placement. Set to 1 to enable. Reset Source: ctl_amod_g_rst_n
  [16] PRIORITY_EN — Enable priority as a rule for command queue placement. Set to 1 to enable. Reset Source: ctl_amod_g_rst_n
  [8] PLACEMENT_EN — Enable placement logic for command queue. Set to 1 to enable. Reset Source: ctl_amod_g_rst_n
  [0] BANK_SPLIT_EN — Enable bank splitting as a rule for command queue placement. Set to 1 to enable. Reset Source: ctl_amod_g_rst_n
0x514 DDR16SS_CTLPHY_WRAP_CTL_CFG_CTLCFG_DENALI_CTL_325
  [25:24] DISABLE_RW_GROUP_W_BNK_CONFLICT — Disables placement to read/write group when grouping creates a bank collision. Bit [0] controls placement next to bank conflict command and bit [1] controls placement 2 away from bank conflict command. Set each bit to 1 to disable. Reset Source: ctl_amod_g_rst_n
  [16] W2R_SPLIT_EN — Enable splitting of commands to the same chip select from a write to a read command as a rule for command queue placement. Reset Source: ctl_amod_g_rst_n
  [8] CS_SAME_EN — Enable chip select grouping when read/write grouping as a rule for command queue placement. This is only valid when the RW_SAME_EN parameter is set. Set to 1 to enable. Reset Source: ctl_amod_g_rst_n
  [0] RW_SAME_PAGE_EN — Enable page grouping when read/write grouping as a rule for command queue placement. This is only valid when the RW_SAME_EN parameter is set. Set to 1 to enable. Reset Source: ctl_amod_g_rst_n
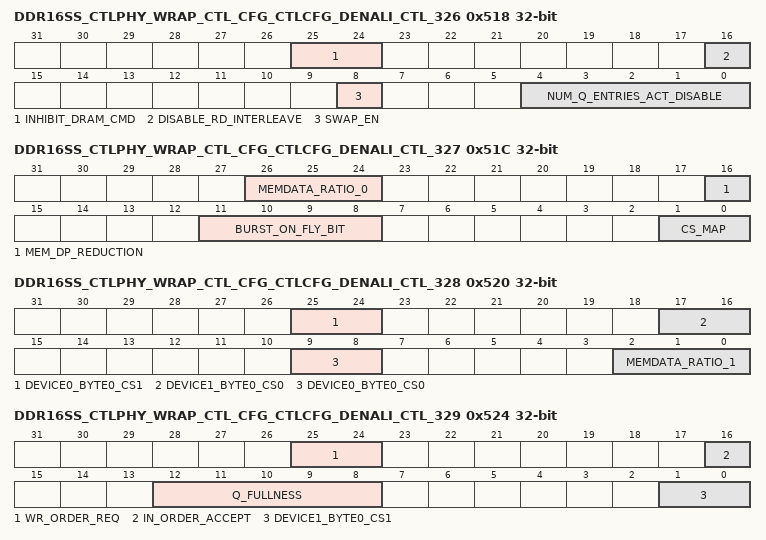
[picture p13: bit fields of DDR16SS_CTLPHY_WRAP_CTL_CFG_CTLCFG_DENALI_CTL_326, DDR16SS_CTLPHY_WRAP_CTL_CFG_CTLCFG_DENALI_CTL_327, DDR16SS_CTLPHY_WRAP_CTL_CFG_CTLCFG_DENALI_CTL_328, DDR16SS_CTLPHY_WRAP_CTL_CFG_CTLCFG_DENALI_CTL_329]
0x518 DDR16SS_CTLPHY_WRAP_CTL_CFG_CTLCFG_DENALI_CTL_326
  [25:24] INHIBIT_DRAM_CMD — Inhibit command types from being executed from the command queue. Clear to 0 to enable any command, program to 1 to inhibit read/write and bank commands, program to 2 to inhibit MRR and peripheral MRR commands, or program to 3 to inhibit MRR and read/write commands. Reset Source: ctl_amod_g_rst_n
  [16] DISABLE_RD_INTERLEAVE — Disable read data interleaving for commands from the same port, regardless of the requestor ID. Reset Source: ctl_amod_g_rst_n
  [8] SWAP_EN — Enable command swapping logic in execution unit. Set to 1 to enable. Reset Source: ctl_amod_g_rst_n
  [4:0] NUM_Q_ENTRIES_ACT_DISABLE — Number of queue entries in which ACT requests will be disabled. Programming to X will disable ACT requests from the X entries lowest in the command queue. Reset Source: ctl_amod_g_rst_n
0x51C DDR16SS_CTLPHY_WRAP_CTL_CFG_CTLCFG_DENALI_CTL_327
  [26:24] MEMDATA_RATIO_0 — Defines the ratio of the DRAM device size on chip select 0 to the memory data width. Program with the log2 ratio of the memory data width to the device data width. CS=0 Reset Source: ctl_amod_g_rst_n
  [16] MEM_DP_REDUCTION — Enable the half datapath feature of the controller. Set to 1 to enable. Reset Source: ctl_amod_g_rst_n
  [11:8] BURST_ON_FLY_BIT — Identifies the burst-on-fly bit in the memory mode registers. Reset Source: ctl_amod_g_rst_n
  [1:0] CS_MAP — Defines which chip selects are active. Reset Source: ctl_amod_g_rst_n
0x520 DDR16SS_CTLPHY_WRAP_CTL_CFG_CTLCFG_DENALI_CTL_328
  [25:24] DEVICE0_BYTE0_CS1 — Defines the byte location of byte0 in the memory datapath for device 0 on chip 1. Used for MRRs to identify where data will be returned. DEV=0 Reset Source: ctl_amod_g_rst_n
  [17:16] DEVICE1_BYTE0_CS0 — Defines the byte location of byte0 in the memory datapath for device 1 on chip 0. Used for MRRs to identify where data will be returned. DEV=1 Reset Source: ctl_amod_g_rst_n
  [9:8] DEVICE0_BYTE0_CS0 — Defines the byte location of byte0 in the memory datapath for device 0 on chip 0. Used for MRRs to identify where data will be returned. DEV=0 Reset Source: ctl_amod_g_rst_n
  [2:0] MEMDATA_RATIO_1 — Defines the ratio of the DRAM device size on chip select 1 to the memory data width. Program with the log2 ratio of the memory data width to the device data width. CS=1 Reset Source: ctl_amod_g_rst_n
0x524 DDR16SS_CTLPHY_WRAP_CTL_CFG_CTLCFG_DENALI_CTL_329
  [25:24] WR_ORDER_REQ — Determines if the controller can re-order write commands from the same source ID and/or the same port. Bit [0] controls source ID usage and bit [1] controls port ID usage. Set each bit to 1 to enable usage in placement logic. Reset Source: ctl_amod_g_rst_n
  [16] IN_ORDER_ACCEPT — Forces the controller to accept commands in the order in which they are placed in the command queue. Reset Source: ctl_amod_g_rst_n
  [12:8] Q_FULLNESS — Quantity that determines when the command queue almost full signal will assert [q_almost_full]. When cleared to 0, the q_almost_full signal will be driven to 0 irrespective of number of entries in the command queue. Reset Source: ctl_amod_g_rst_n
  [1:0] DEVICE1_BYTE0_CS1 — Defines the byte location of byte0 in the memory datapath for device 1 on chip 1. Used for MRRs to identify where data will be returned. DEV=1 Reset Source: ctl_amod_g_rst_n
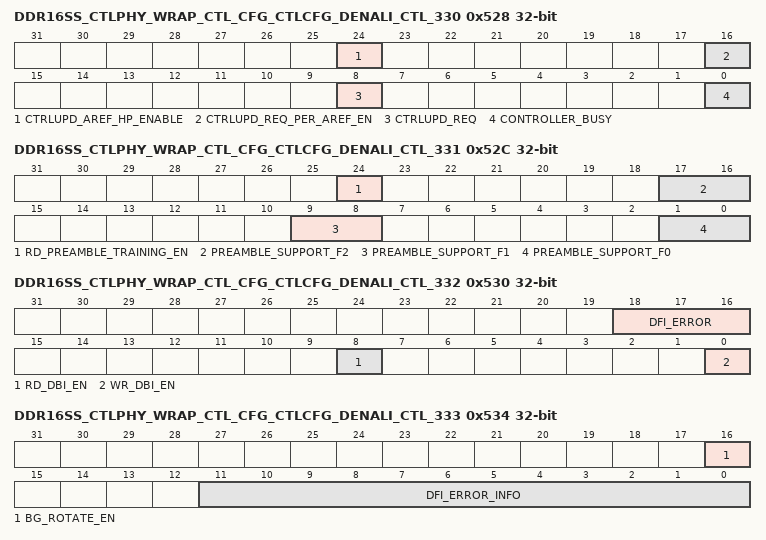
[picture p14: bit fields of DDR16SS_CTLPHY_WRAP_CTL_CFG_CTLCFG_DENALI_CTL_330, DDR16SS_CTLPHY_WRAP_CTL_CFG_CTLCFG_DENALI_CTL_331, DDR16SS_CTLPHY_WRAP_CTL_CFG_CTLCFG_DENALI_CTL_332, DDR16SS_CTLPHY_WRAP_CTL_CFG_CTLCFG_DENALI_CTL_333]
0x528 DDR16SS_CTLPHY_WRAP_CTL_CFG_CTLCFG_DENALI_CTL_330 access per field
  [24] CTRLUPD_AREF_HP_ENABLE rw — Enable an automatic controller-initiated update [dfi_ctrlupd_req] after every high priority refresh when executing as a subtask request. Set to 1 to enable. Reset Source: ctl_amod_g_rst_n
  [16] CTRLUPD_REQ_PER_AREF_EN rw — Enable an automatic controller-initiated update [dfi_ctrlupd_req] after every refresh. Set to 1 to enable. Reset Source: ctl_amod_g_rst_n
  [8] CTRLUPD_REQ wo — Assert the DFI controller-initiated update request signal dfi_ctrlupd_req. Set to 1 to trigger. WRITE-ONLY Reset Source: ctl_amod_g_rst_n
  [0] CONTROLLER_BUSY ro — Indicator that the controller is processing a command. Evaluates all ports for outstanding transactions. Value of 1 indicates controller busy. READ-ONLY Reset Source: ctl_amod_g_rst_n
0x52C DDR16SS_CTLPHY_WRAP_CTL_CFG_CTLCFG_DENALI_CTL_331
  [24] RD_PREAMBLE_TRAINING_EN — Enable read preamble training during gate training. Set to 1 to enable. Reset Source: ctl_amod_g_rst_n
  [17:16] PREAMBLE_SUPPORT_F2 — Selection the preamble for read and write burst transfers. FC=2 Reset Source: ctl_amod_g_rst_n
  [9:8] PREAMBLE_SUPPORT_F1 — Selection the preamble for read and write burst transfers. FC=1 Reset Source: ctl_amod_g_rst_n
  [1:0] PREAMBLE_SUPPORT_F0 — Selection the preamble for read and write burst transfers. FC=0 Reset Source: ctl_amod_g_rst_n
0x530 DDR16SS_CTLPHY_WRAP_CTL_CFG_CTLCFG_DENALI_CTL_332 access per field
  [18:16] DFI_ERROR ro — Indicates that the DFI error flag has been asserted. READ-ONLY Reset Source: ctl_amod_g_rst_n
  [8] RD_DBI_EN rw — Enables controller support of DRAM DBI feature for read data with DDR4 devices. Set to 1 to enable. Reset Source: ctl_amod_g_rst_n
  [0] WR_DBI_EN rw — Enables controller support of DRAM DBI feature for write data with DDR4 devices. Set to 1 to enable. Reset Source: ctl_amod_g_rst_n
0x534 DDR16SS_CTLPHY_WRAP_CTL_CFG_CTLCFG_DENALI_CTL_333 access per field
  [16] BG_ROTATE_EN rw — Enable bank group rotation. Set to 1 to enable. Reset Source: ctl_amod_g_rst_n
  [11:0] DFI_ERROR_INFO ro — Holds the encoded DFI error type associated with the DFI_ERROR parameter assertion. READ-ONLY Reset Source: ctl_amod_g_rst_n
0x538 DDR16SS_CTLPHY_WRAP_CTL_CFG_CTLCFG_DENALI_CTL_334 ro
  [31:0] INT_STATUS_MASTER — Master status reporting register for interrupt status groups. READ-ONLY Reset Source: ctl_amod_g_rst_n
0x53C DDR16SS_CTLPHY_WRAP_CTL_CFG_CTLCFG_DENALI_CTL_335
  [31:0] INT_MASK_MASTER — Master mask register for interrupt status groups. WRITE-ONLY Reset Source: ctl_amod_g_rst_n
0x540 DDR16SS_CTLPHY_WRAP_CTL_CFG_CTLCFG_DENALI_CTL_336 ro
  [31:0] INT_STATUS_TIMEOUT — Status of interrupts in the controller related to Timeout monitors. READ-ONLY Reset Source: ctl_amod_g_rst_n
0x544 DDR16SS_CTLPHY_WRAP_CTL_CFG_CTLCFG_DENALI_CTL_337 ro
  [31:16] INT_STATUS_LOWPOWER — Status of interrupts in the controller related to Low Power. READ-ONLY Reset Source: ctl_amod_g_rst_n
0x548 DDR16SS_CTLPHY_WRAP_CTL_CFG_CTLCFG_DENALI_CTL_338 access not given reset not defined
0x54C DDR16SS_CTLPHY_WRAP_CTL_CFG_CTLCFG_DENALI_CTL_339 ro
  [31:0] INT_STATUS_TRAINING — Status of interrupts in the controller related to Training/Calibration. READ-ONLY Reset Source: ctl_amod_g_rst_n
0x550 DDR16SS_CTLPHY_WRAP_CTL_CFG_CTLCFG_DENALI_CTL_340 ro
  [31:0] INT_STATUS_USERIF — Status of interrupts in the controller related to ASIC to Controller Interface. READ-ONLY Reset Source: ctl_amod_g_rst_n
0x554 DDR16SS_CTLPHY_WRAP_CTL_CFG_CTLCFG_DENALI_CTL_341 ro
  [23:16] INT_STATUS_BIST — Status of interrupts in the controller related to BIST. READ-ONLY Reset Source: ctl_amod_g_rst_n
  [15:0] INT_STATUS_MISC — Status of interrupts in the controller related to Miscellaneous features. READ-ONLY Reset Source: ctl_amod_g_rst_n
0x558 DDR16SS_CTLPHY_WRAP_CTL_CFG_CTLCFG_DENALI_CTL_342 ro
  [31:24] INT_STATUS_INIT — Status of interrupts in the controller related to Initialization. READ-ONLY Reset Source: ctl_amod_g_rst_n
  [23:16] INT_STATUS_FREQ — Status of interrupts in the controller related to Frequency Scaling. READ-ONLY Reset Source: ctl_amod_g_rst_n
  [7:0] INT_STATUS_DFI — Status of interrupts in the controller related to DFI. READ-ONLY Reset Source: ctl_amod_g_rst_n
0x55C DDR16SS_CTLPHY_WRAP_CTL_CFG_CTLCFG_DENALI_CTL_343 ro
  [15:8] INT_STATUS_PARITY — Status of interrupts in the controller related to Parity. READ-ONLY Reset Source: ctl_amod_g_rst_n
  [7:0] INT_STATUS_MODE — Status of interrupts in the controller related to Memory Mode Settings. READ-ONLY Reset Source: ctl_amod_g_rst_n
0x560 DDR16SS_CTLPHY_WRAP_CTL_CFG_CTLCFG_DENALI_CTL_344 wo
  [31:0] INT_ACK_TIMEOUT — Clear status of the INT_STATUS_TIMEOUT parameter. WRITE-ONLY Reset Source: ctl_amod_g_rst_n
0x564 DDR16SS_CTLPHY_WRAP_CTL_CFG_CTLCFG_DENALI_CTL_345 wo
  [31:16] INT_ACK_LOWPOWER — Clear status of the INT_STATUS_LOWPOWER parameter. WRITE-ONLY Reset Source: ctl_amod_g_rst_n
0x568 DDR16SS_CTLPHY_WRAP_CTL_CFG_CTLCFG_DENALI_CTL_346 access not given reset not defined
0x56C DDR16SS_CTLPHY_WRAP_CTL_CFG_CTLCFG_DENALI_CTL_347 wo
  [31:0] INT_ACK_TRAINING — Clear status of the INT_STATUS_TRAINING parameter. WRITE-ONLY Reset Source: ctl_amod_g_rst_n
0x570 DDR16SS_CTLPHY_WRAP_CTL_CFG_CTLCFG_DENALI_CTL_348 wo
  [31:0] INT_ACK_USERIF — Clear status of the INT_STATUS_USERIF parameter. WRITE-ONLY Reset Source: ctl_amod_g_rst_n
0x574 DDR16SS_CTLPHY_WRAP_CTL_CFG_CTLCFG_DENALI_CTL_349 wo
  [23:16] INT_ACK_BIST — Clear status of the INT_STATUS_BIST parameter. WRITE-ONLY Reset Source: ctl_amod_g_rst_n
  [15:0] INT_ACK_MISC — Clear status of the INT_STATUS_MISC parameter. WRITE-ONLY Reset Source: ctl_amod_g_rst_n
0x578 DDR16SS_CTLPHY_WRAP_CTL_CFG_CTLCFG_DENALI_CTL_350 wo
  [31:24] INT_ACK_INIT — Clear status of the INT_STATUS_INIT parameter. WRITE-ONLY Reset Source: ctl_amod_g_rst_n
  [23:16] INT_ACK_FREQ — Clear status of the INT_STATUS_FREQ parameter. WRITE-ONLY Reset Source: ctl_amod_g_rst_n
  [7:0] INT_ACK_DFI — Clear status of the INT_STATUS_DFI parameter. WRITE-ONLY Reset Source: ctl_amod_g_rst_n
0x57C DDR16SS_CTLPHY_WRAP_CTL_CFG_CTLCFG_DENALI_CTL_351 wo
  [15:8] INT_ACK_PARITY — Clear status of the INT_STATUS_PARITY parameter. WRITE-ONLY Reset Source: ctl_amod_g_rst_n
  [7:0] INT_ACK_MODE — Clear status of the INT_STATUS_MODE parameter. WRITE-ONLY Reset Source: ctl_amod_g_rst_n
0x580 DDR16SS_CTLPHY_WRAP_CTL_CFG_CTLCFG_DENALI_CTL_352
  [31:0] INT_MASK_TIMEOUT — Mask for the controller_int signal from the INT_MASK_TIMEOUT parameter Reset Source: ctl_amod_g_rst_n
0x584 DDR16SS_CTLPHY_WRAP_CTL_CFG_CTLCFG_DENALI_CTL_353
  [31:16] INT_MASK_LOWPOWER — Mask for the controller_int signal from the INT_MASK_LOWPOWER parameter Reset Source: ctl_amod_g_rst_n
0x588 DDR16SS_CTLPHY_WRAP_CTL_CFG_CTLCFG_DENALI_CTL_354 access not given reset not defined
0x58C DDR16SS_CTLPHY_WRAP_CTL_CFG_CTLCFG_DENALI_CTL_355
  [31:0] INT_MASK_TRAINING — Mask for the controller_int signal from the INT_MASK_TRAINING parameter Reset Source: ctl_amod_g_rst_n
0x590 DDR16SS_CTLPHY_WRAP_CTL_CFG_CTLCFG_DENALI_CTL_356
  [31:0] INT_MASK_USERIF — Mask for the controller_int signal from the INT_MASK_USERIF parameter Reset Source: ctl_amod_g_rst_n
0x594 DDR16SS_CTLPHY_WRAP_CTL_CFG_CTLCFG_DENALI_CTL_357
  [23:16] INT_MASK_BIST — Mask for the controller_int signal from the INT_MASK_BIST parameter Reset Source: ctl_amod_g_rst_n
  [15:0] INT_MASK_MISC — Mask for the controller_int signal from the INT_MASK_MISC parameter Reset Source: ctl_amod_g_rst_n
0x598 DDR16SS_CTLPHY_WRAP_CTL_CFG_CTLCFG_DENALI_CTL_358
  [31:24] INT_MASK_INIT — Mask for the controller_int signal from the INT_MASK_INIT parameter Reset Source: ctl_amod_g_rst_n
  [23:16] INT_MASK_FREQ — Mask for the controller_int signal from the INT_MASK_FREQ parameter Reset Source: ctl_amod_g_rst_n
  [7:0] INT_MASK_DFI — Mask for the controller_int signal from the INT_MASK_DFI parameter Reset Source: ctl_amod_g_rst_n
0x59C DDR16SS_CTLPHY_WRAP_CTL_CFG_CTLCFG_DENALI_CTL_359
  [15:8] INT_MASK_PARITY — Mask for the controller_int signal from the INT_MASK_PARITY parameter Reset Source: ctl_amod_g_rst_n
  [7:0] INT_MASK_MODE — Mask for the controller_int signal from the INT_MASK_MODE parameter Reset Source: ctl_amod_g_rst_n
